VERSION ""

NS_ :

BS_:

BU_: XXX

BO_ 85 CID_MBOURF: 8 XXX
 SG_ sig_uczcao : 40|1@1+ (1,0) [0|1] "" XXX
 SG_ sig_mmmthx : 56|8@1+ (1,0) [0|255] "" XXX

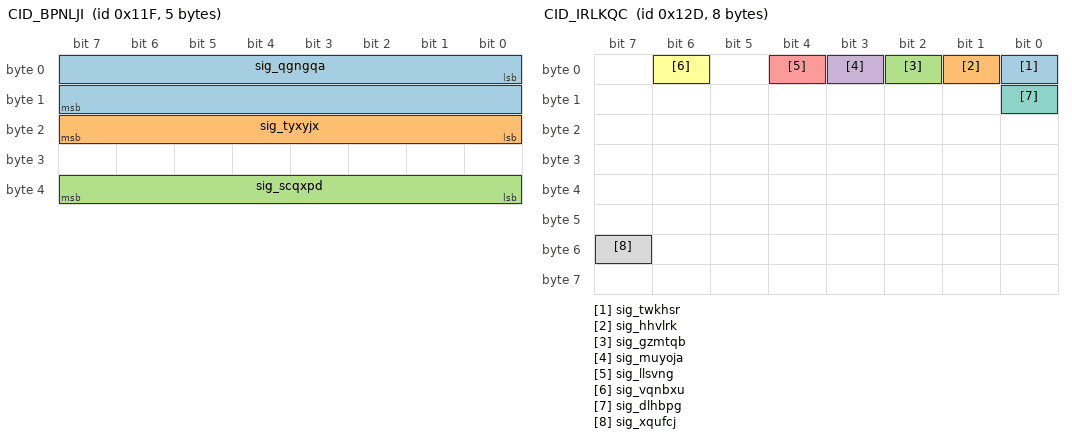
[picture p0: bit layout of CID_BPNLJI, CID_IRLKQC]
BO_ 287 CID_BPNLJI: 5 XXX
 SG_ sig_qgngqa : 0|16@1- (0.1,0) [-450|450] "" XXX
 SG_ sig_tyxyjx : 16|8@1+ (4,0) [0|1020] "" XXX
 SG_ sig_scqxpd : 32|8@1+ (1,0) [0|255] "" XXX

BO_ 289 CID_GURVAF: 8 XXX
 SG_ sig_wcttio : 0|12@1+ (1,0) [0|255] "" XXX

BO_ 301 CID_IRLKQC: 8 XXX
 SG_ sig_twkhsr : 0|1@0+ (1,0) [0|1] "" XXX
 SG_ sig_hhvlrk : 1|1@0+ (1,0) [0|1] "" XXX
 SG_ sig_gzmtqb : 2|1@0+ (1,0) [0|1] "" XXX
 SG_ sig_muyoja : 3|1@0+ (1,0) [0|1] "" XXX
 SG_ sig_llsvng : 4|1@0+ (1,0) [0|1] "" XXX
 SG_ sig_vqnbxu : 6|1@0+ (1,0) [0|1] "" XXX
 SG_ sig_dlhbpg : 8|1@0+ (1,0) [0|1] "" XXX
 SG_ sig_xqufcj : 55|1@0+ (1,0) [0|1] "" XXX

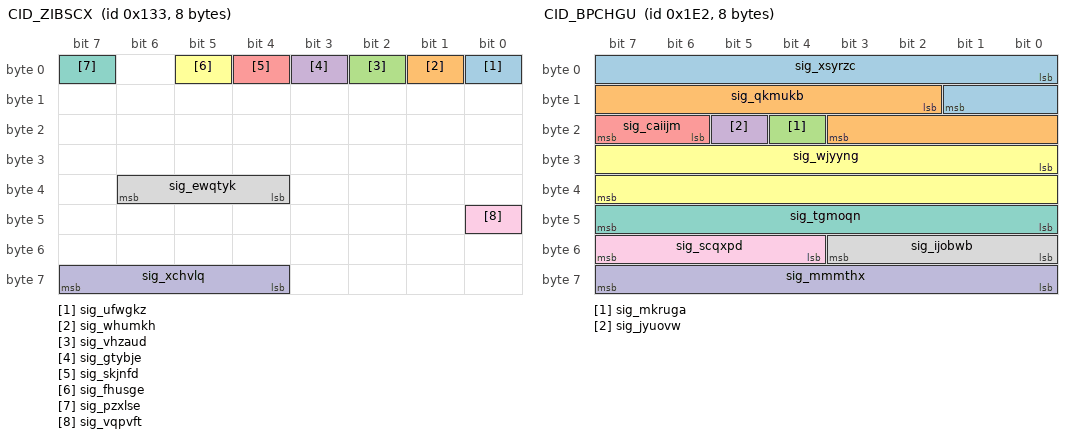
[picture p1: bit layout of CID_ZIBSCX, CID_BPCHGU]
BO_ 307 CID_ZIBSCX: 8 XXX
 SG_ sig_ufwgkz : 0|1@0+ (1,0) [0|1] "" XXX
 SG_ sig_whumkh : 1|1@1+ (1,0) [0|1] "" XXX
 SG_ sig_vhzaud : 2|1@1+ (1,0) [0|1] "" XXX
 SG_ sig_gtybje : 3|1@1+ (1,0) [0|1] "" XXX
 SG_ sig_skjnfd : 4|1@0+ (1,0) [0|1] "" XXX
 SG_ sig_fhusge : 5|1@0+ (1,0) [0|1] "" XXX
 SG_ sig_pzxlse : 7|1@0+ (1,0) [0|1] "" XXX
 SG_ sig_ewqtyk : 36|3@1+ (1,0) [0|7] "" XXX
 SG_ sig_vqpvft : 40|1@0+ (1,0) [0|1] "" XXX
 SG_ sig_xchvlq : 63|4@0+ (1,0) [0|15] "" XXX

BO_ 482 CID_BPCHGU: 8 XXX
 SG_ sig_xsyrzc : 0|10@1- (0.01,0) [0|5] "" XXX
 SG_ sig_qkmukb : 10|10@1- (0.01,0) [-5|0] "" XXX
 SG_ sig_mkruga : 20|1@0+ (1,0) [0|1] "" XXX
 SG_ sig_jyuovw : 21|1@0+ (1,0) [0|1] "" XXX
 SG_ sig_caiijm : 22|2@1+ (1,0) [0|1] "" XXX
 SG_ sig_wjyyng : 24|16@1- (0.1,0) [-780|779.9] "" XXX
 SG_ sig_tgmoqn : 47|8@0+ (1,0) [0|255] "" XXX
 SG_ sig_ijobwb : 48|4@1+ (1,0) [0|15] "" XXX
 SG_ sig_scqxpd : 52|4@1+ (1,0) [0|15] "" XXX
 SG_ sig_mmmthx : 56|8@1+ (1,0) [0|255] "" XXX

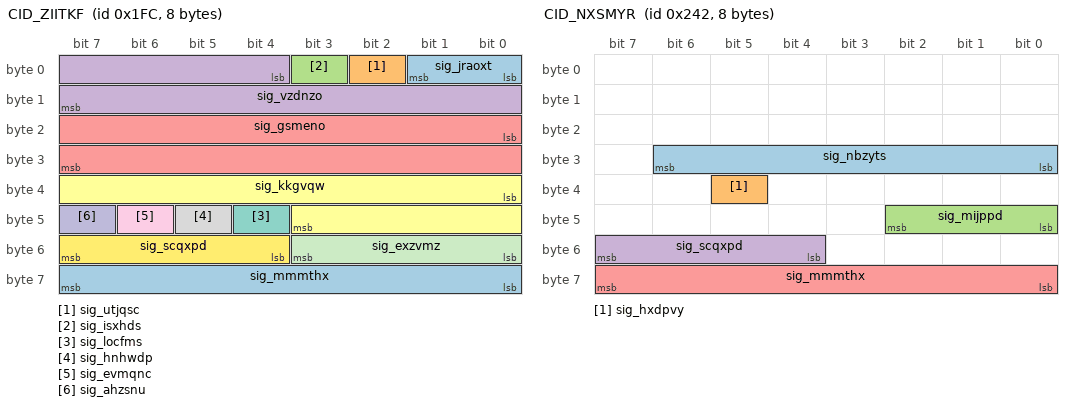
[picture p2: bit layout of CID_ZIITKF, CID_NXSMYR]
BO_ 508 CID_ZIITKF: 8 XXX
 SG_ sig_jraoxt : 0|2@1+ (1,0) [0|1] "" XXX
 SG_ sig_utjqsc : 2|1@1+ (1,0) [0|1] "" XXX
 SG_ sig_isxhds : 3|1@0+ (1,0) [0|1] "" XXX
 SG_ sig_vzdnzo : 4|12@1- (1,0) [-2048|2047] "" XXX
 SG_ sig_gsmeno : 16|16@1- (0.1,0) [-780|779.9] "Deg" XXX
 SG_ sig_kkgvqw : 32|12@1- (0.01,0) [0|63] "" XXX
 SG_ sig_locfms : 44|1@0+ (1,0) [0|1] "" XXX
 SG_ sig_hnhwdp : 45|1@1+ (1,0) [0|255] "" XXX
 SG_ sig_evmqnc : 46|1@1+ (1,0) [0|1] "" XXX
 SG_ sig_ahzsnu : 47|1@0+ (1,0) [0|3] "" XXX
 SG_ sig_exzvmz : 48|4@1+ (1,0) [0|15] "" XXX
 SG_ sig_scqxpd : 52|4@1+ (1,0) [0|15] "" XXX
 SG_ sig_mmmthx : 56|8@1+ (1,0) [0|255] "" XXX

BO_ 578 CID_NXSMYR: 8 XXX
 SG_ sig_nbzyts : 30|7@0+ (1,0) [0|127] "" XXX
 SG_ sig_hxdpvy : 37|1@0+ (1,0) [0|1] "" XXX
 SG_ sig_mijppd : 40|3@1+ (1,0) [0|7] "" XXX
 SG_ sig_scqxpd : 55|4@0+ (1,0) [0|15] "" XXX
 SG_ sig_mmmthx : 56|8@1+ (1,0) [0|255] "" XXX

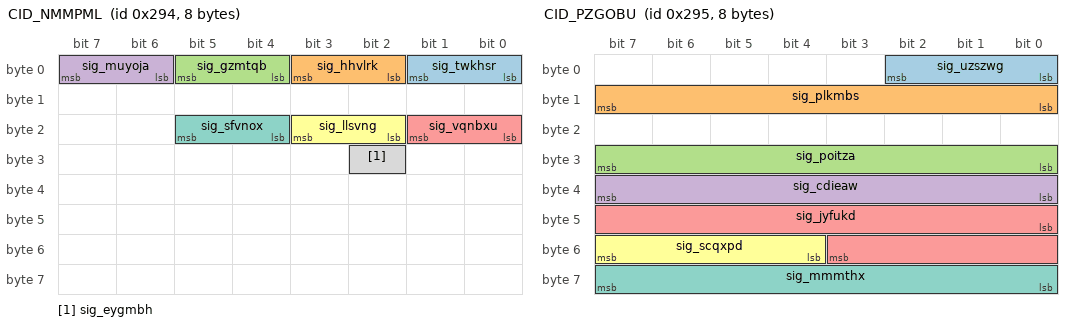
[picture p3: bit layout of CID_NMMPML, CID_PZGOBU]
BO_ 660 CID_NMMPML: 8 XXX
 SG_ sig_twkhsr : 1|2@0+ (1,0) [0|3] "" XXX
 SG_ sig_hhvlrk : 3|2@0+ (1,0) [0|3] "" XXX
 SG_ sig_gzmtqb : 5|2@0+ (1,0) [0|3] "" XXX
 SG_ sig_muyoja : 7|2@0+ (1,0) [0|3] "" XXX
 SG_ sig_vqnbxu : 17|2@0+ (1,0) [0|3] "" XXX
 SG_ sig_llsvng : 19|2@0+ (1,0) [0|3] "" XXX
 SG_ sig_sfvnox : 21|2@0+ (1,0) [0|3] "" XXX
 SG_ sig_eygmbh : 26|1@0+ (1,0) [0|1] "" XXX

BO_ 661 CID_PZGOBU: 8 XXX
 SG_ sig_uzszwg : 2|3@0+ (1,0) [0|7] "" XXX
 SG_ sig_plkmbs : 15|8@0+ (1,0) [0|255] "" XXX
 SG_ sig_poitza : 31|8@0+ (1,0) [0|255] "" XXX
 SG_ sig_cdieaw : 32|8@1+ (1,0) [0|255] "" XXX
 SG_ sig_jyfukd : 40|12@1+ (1,0) [0|255] "" XXX
 SG_ sig_scqxpd : 52|4@1+ (1,0) [0|15] "" XXX
 SG_ sig_mmmthx : 63|8@0+ (1,0) [0|255] "" XXX

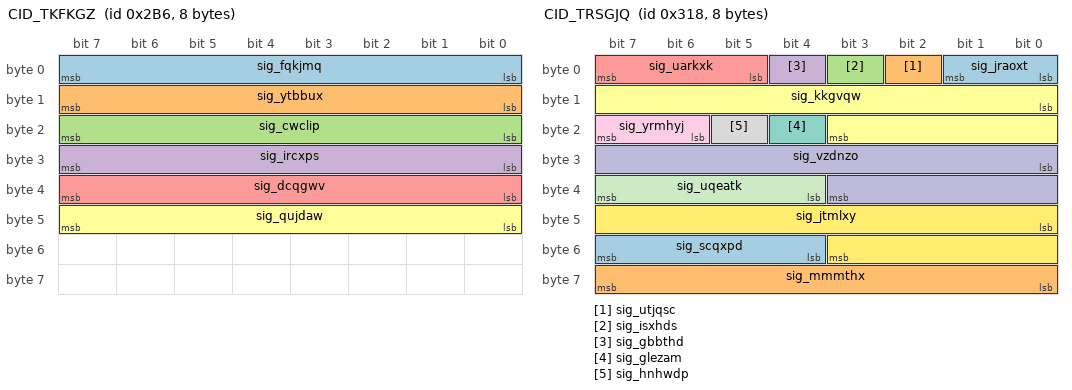
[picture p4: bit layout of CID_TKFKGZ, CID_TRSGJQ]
BO_ 694 CID_TKFKGZ: 8 XXX
 SG_ sig_fqkjmq : 7|8@0+ (1,0) [0|255] "" XXX
 SG_ sig_ytbbux : 15|8@0+ (1,0) [0|255] "" XXX
 SG_ sig_cwclip : 23|8@0+ (1,0) [0|255] "" XXX
 SG_ sig_ircxps : 31|8@0+ (1,0) [0|255] "" XXX
 SG_ sig_dcqgwv : 39|8@0+ (1,0) [0|255] "" XXX
 SG_ sig_qujdaw : 47|8@0+ (1,0) [0|255] "" XXX

BO_ 790 CID_LEXJLS: 8 XXX
 SG_ sig_tvrmwr : 3|4@0+ (1,0) [0|1] "" XXX
 SG_ sig_msbifo : 4|2@1+ (1,0) [0|3] "" XXX
 SG_ sig_czlpsu : 6|2@1+ (1,0) [0|3] "" XXX
 SG_ sig_kohwbx : 8|2@1+ (1,0) [0|3] "" XXX
 SG_ sig_vavopy : 10|1@1+ (1,0) [0|1] "" XXX
 SG_ sig_rkueqc : 11|4@1+ (1,0) [0|1] "" XXX
 SG_ sig_punegz : 15|1@0+ (1,0) [0|1] "" XXX
 SG_ sig_wjyyng : 16|11@1- (1,0) [-1024|1023] "" XXX
 SG_ sig_mkruga : 27|1@1+ (1,0) [0|1] "" XXX
 SG_ sig_jyuovw : 28|1@1+ (1,0) [0|3] "" XXX
 SG_ sig_yjecoo : 29|1@0+ (1,0) [0|1] "" XXX
 SG_ sig_iglzap : 30|1@0+ (1,0) [0|1] "" XXX
 SG_ sig_xupjps : 31|1@0+ (1,0) [0|1] "" XXX
 SG_ sig_edvrbo : 32|2@1+ (1,0) [0|3] "" XXX
 SG_ sig_zqggpd : 34|2@1+ (1,0) [0|3] "" XXX
 SG_ sig_nljcyf : 36|4@1+ (1,0) [0|3] "" XXX
 SG_ sig_xntogz : 40|8@1+ (5,-5) [-5|1270] "" XXX
 SG_ sig_uhlmkg : 49|2@0+ (1,0) [0|3] "" XXX
 SG_ sig_thfttp : 51|2@0+ (1,0) [0|3] "" XXX
 SG_ sig_scqxpd : 52|4@1+ (1,0) [0|15] "" XXX
 SG_ sig_mmmthx : 56|8@1+ (1,0) [0|15] "" XXX

BO_ 792 CID_TRSGJQ: 8 XXX
 SG_ sig_jraoxt : 0|2@1+ (1,0) [0|1] "" XXX
 SG_ sig_utjqsc : 2|1@1+ (1,0) [0|1] "" XXX
 SG_ sig_isxhds : 3|1@1+ (1,0) [0|1] "" XXX
 SG_ sig_gbbthd : 4|1@1+ (1,0) [0|1] "" XXX
 SG_ sig_uarkxk : 5|3@1+ (1,0) [0|1] "" XXX
 SG_ sig_kkgvqw : 8|12@1- (1,0) [-2048|2047] "" XXX
 SG_ sig_glezam : 20|1@1+ (1,0) [0|1] "" XXX
 SG_ sig_hnhwdp : 21|1@1+ (1,0) [0|1] "" XXX
 SG_ sig_yrmhyj : 22|2@1+ (1,0) [0|15] "" XXX
 SG_ sig_vzdnzo : 24|12@1- (1,0) [-2048|2047] "" XXX
 SG_ sig_uqeatk : 36|4@1+ (1,0) [0|15] "" XXX
 SG_ sig_jtmlxy : 40|12@1+ (1,0) [0|4095] "" XXX
 SG_ sig_scqxpd : 52|4@1+ (1,0) [0|15] "" XXX
 SG_ sig_mmmthx : 56|8@1+ (1,0) [0|255] "" XXX

BO_ 813 CID_PCMGMH: 8 XXX
 SG_ sig_yjszns : 0|9@1+ (0.5,0) [0|255.5] "" XXX
 SG_ sig_ywvfll : 9|1@1+ (1,0) [0|1] "" XXX
 SG_ sig_upimyp : 10|3@1+ (1,0) [0|7] "" XXX
 SG_ sig_ypuaji : 13|3@1+ (1,0) [0|7] "" XXX
 SG_ sig_xoibxq : 16|1@1+ (1,0) [0|1] "" XXX
 SG_ sig_joxrir : 17|1@1+ (1,0) [0|1] "" XXX
 SG_ sig_isxhds : 18|1@1+ (1,0) [0|1] "" XXX
 SG_ sig_vhwmen : 19|3@1+ (1,0) [0|1] "" XXX
 SG_ sig_xasjpq : 22|1@0+ (1,0) [0|1] "" XXX
 SG_ sig_cvxist : 23|1@0+ (1,0) [0|1] "" XXX
 SG_ sig_kohwbx : 24|1@1+ (1,0) [0|1] "" XXX
 SG_ sig_nhzwri : 25|7@1+ (1,0) [0|127] "" XXX
 SG_ sig_srblrj : 32|4@1+ (1,0) [0|15] "" XXX
 SG_ sig_tjnsfz : 36|12@1+ (1,0) [0|4095] "" XXX
 SG_ sig_scqxpd : 48|4@1+ (1,0) [0|15] "" XXX
 SG_ sig_qosmbx : 55|4@0+ (1,0) [0|15] "" XXX
 SG_ sig_mmmthx : 56|8@1+ (1,0) [0|255] "" XXX

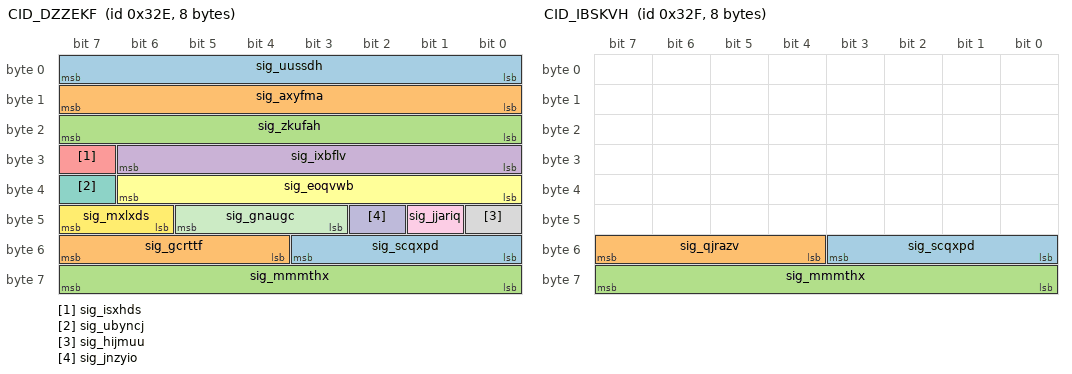
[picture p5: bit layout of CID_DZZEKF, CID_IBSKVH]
BO_ 814 CID_DZZEKF: 8 XXX
 SG_ sig_uussdh : 0|8@1+ (0.05,-5) [-100|155] "" XXX
 SG_ sig_axyfma : 8|8@1+ (0.05,-5) [0|1.26] "" XXX
 SG_ sig_zkufah : 16|8@1+ (0.05,-5) [0|1.26] "" XXX
 SG_ sig_ixbflv : 24|7@1+ (0.2,0) [0|12.7] "" XXX
 SG_ sig_isxhds : 31|1@0+ (1,0) [0|1] "" XXX
 SG_ sig_eoqvwb : 32|7@1+ (0.2,-16) [0|12.7] "" XXX
 SG_ sig_ubyncj : 39|1@0+ (1,0) [0|1] "" XXX
 SG_ sig_hijmuu : 40|1@0+ (1,0) [0|1] "" XXX
 SG_ sig_jjariq : 41|1@0+ (1,0) [0|1] "" XXX
 SG_ sig_jnzyio : 42|1@1+ (1,0) [0|3] "" XXX
 SG_ sig_gnaugc : 45|3@0+ (1,0) [0|1] "" XXX
 SG_ sig_mxlxds : 46|2@1+ (1,0) [0|3] "" XXX
 SG_ sig_scqxpd : 48|4@1+ (1,0) [0|15] "" XXX
 SG_ sig_gcrttf : 55|4@0+ (1,0) [0|15] "" XXX
 SG_ sig_mmmthx : 56|8@1+ (1,0) [0|255] "" XXX

BO_ 815 CID_IBSKVH: 8 XXX
 SG_ sig_scqxpd : 48|4@1+ (1,0) [0|15] "" XXX
 SG_ sig_qjrazv : 55|4@0+ (1,0) [0|15] "" XXX
 SG_ sig_mmmthx : 56|8@1+ (1,0) [0|255] "" XXX

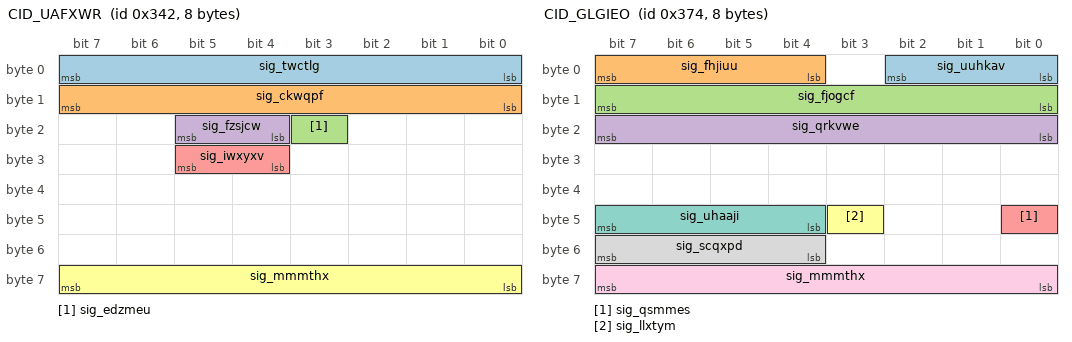
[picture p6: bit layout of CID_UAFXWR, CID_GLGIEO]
BO_ 834 CID_UAFXWR: 8 XXX
 SG_ sig_twctlg : 0|8@1+ (0.01,0) [0|2.55] "" XXX
 SG_ sig_ckwqpf : 8|8@1+ (0.01,0) [0|2.55] "" XXX
 SG_ sig_edzmeu : 19|1@1+ (1,0) [0|1] "" XXX
 SG_ sig_fzsjcw : 20|2@1+ (1,0) [0|255] "" XXX
 SG_ sig_iwxyxv : 28|2@1+ (1,0) [0|1] "" XXX
 SG_ sig_mmmthx : 56|8@1+ (1,0) [0|255] "" XXX

 BO_ 884 CID_GLGIEO: 8 MRR
 SG_ sig_uuhkav : 2|3@0+ (1,0) [0|3] "" MRR
 SG_ sig_fhjiuu : 7|4@0+ (1,0) [0|15] "" MRR
 SG_ sig_fjogcf : 15|8@0+ (0.1,-12) [0|255] "" MRR
 SG_ sig_qrkvwe : 23|8@0+ (1,-100) [0|255] "" MRR
 SG_ sig_qsmmes : 40|1@0+ (1,0) [0|3] "" MRR
 SG_ sig_llxtym : 43|1@0+ (1,0) [0|1] "" XXX
 SG_ sig_uhaaji : 44|4@1+ (1,0) [0|15] "" XXX
 SG_ sig_scqxpd : 52|4@1+ (1,0) [0|15] "" MRR
 SG_ sig_mmmthx : 56|8@1+ (1,0) [0|255] "" MRR

BO_ 944 CID_TYBJQP: 8 XXX
 SG_ sig_dlxaxh : 1|2@0+ (1,0) [0|3] "" XXX
 SG_ sig_qxzryt : 2|1@0+ (1,0) [0|1] "" XXX
 SG_ sig_ubthby : 4|2@0+ (1,0) [0|3] "" XXX
 SG_ sig_oyfdit : 5|1@0+ (1,0) [0|1] "" XXX
 SG_ sig_oakpyw : 6|1@0+ (1,0) [0|1] "" XXX
 SG_ sig_tzxiwr : 7|1@0+ (1,0) [0|1] "" XXX
 SG_ sig_miolsw : 8|1@0+ (1,0) [0|1] "" XXX
 SG_ sig_jozqxw : 11|3@0+ (1,0) [0|7] "" XXX
 SG_ sig_odwcjw : 12|1@0+ (1,0) [0|1] "" XXX
 SG_ sig_lggbrm : 14|2@0+ (1,0) [0|3] "" XXX
 SG_ sig_wctpwf : 15|1@0+ (1,0) [0|1] "" XXX
 SG_ sig_apnmdh : 16|1@0+ (1,0) [0|1] "" XXX
 SG_ sig_itnfhz : 18|2@0+ (1,0) [0|3] "" XXX
 SG_ sig_ljlmqk : 19|1@0+ (1,0) [0|1] "" XXX
 SG_ sig_qncvob : 23|4@0+ (1,0) [0|15] "" XXX
 SG_ sig_aevazw : 24|28@1+ (1,0) [0|268435455] "" XXX
 SG_ sig_scqxpd : 52|4@1+ (1,0) [0|15] "" XXX
 SG_ sig_mmmthx : 56|8@1+ (1,0) [0|255] "" XXX

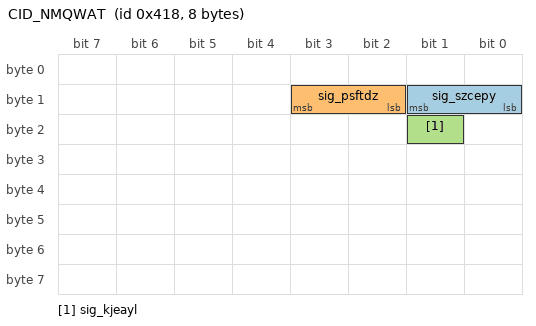
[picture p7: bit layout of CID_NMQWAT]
BO_ 1048 CID_NMQWAT: 8 XXX
 SG_ sig_szcepy : 9|2@0+ (1,0) [0|1] "" XXX
 SG_ sig_psftdz : 11|2@0+ (1,0) [0|1] "" XXX
 SG_ sig_kjeayl : 17|1@0+ (1,0) [0|1] "" XXX

VAL_ 578 sig_mijppd 4 "D" 2 "R" 3 "N" 1 "P";
VAL_ 790 sig_tvrmwr 11 "AutoFullBeamActive" 2 "AutoFullBeamInactive";
VAL_ 790 sig_msbifo 0 "GRAY" 1 "GREEN" 2 "YELLOW" 3 "RED";
VAL_ 790 sig_czlpsu 3 "ALARM_AND_LKA" 2 "LKA" 1 "ALARM" 0 "DISABLE";
VAL_ 790 sig_zqggpd 0 "GRAY" 1 "GREEN" 2 "YELLOW" 3 "RED";
VAL_ 790 sig_uhlmkg 0 "VIBRATION" 1 "AUDIO" 2 "AUDIO_AND_VIBRATION";
VAL_ 792 sig_jraoxt 0 "NotReady" 1 "Ready" 2 "Active" 3 "TemporaryFail";
VAL_ 813 sig_upimyp 4 "4BAR" 3 "3BAR" 2 "2BAR" 1 "1BAR";
VAL_ 813 sig_vhwmen 0 "OFF" 2 "ACC_ON" 3 "ACC_ACTIVE" 5 "FORCE_ACCEL" 7 "ERROR";
VAL_ 813 sig_nhzwri 36 "ACC_ERROR" 22 "OVERRIDE" 12 "ENGAGE" 8 "DISENGAGE" 20 "ACC_ON" 32 "ACC_OFF" 48 "CHECK_GEAR_D" 16 "FORCE_ACCEL" 0 "NONE";
VAL_ 814 sig_gnaugc 0 "Off" 1 "Passive" 2 "StandBy" 3 "ActiveControl" 4 "BrakeOnly" 5 "Override" 6 "Standstill" 7 "Failure";
VAL_ 814 sig_mxlxds 0 "Softoff" 1 "Fastoff" 2 "Immediateoff" 3 "Initial";
VAL_ 834 sig_fzsjcw 2 "SPORT" 1 "ECO" 0 "SNOW";
VAL_ 834 sig_iwxyxv 3 "HEV" 2 "FORCE_EV" 1 "EV";
VAL_ 944 sig_ubthby 0 "NOTPRESSED" 1 "DOWN_SETSPEED" 3 "UP_RESETSPEED";
